# ATSAMD20J16B device description
Architecture: CORTEX-M0PLUS; Family: SAMD; Series: SAMD20
Registers are 8-bit, read-write, reset 0x0 unless marked. A register's access mark holds for its fields unless they carry their own. Offsets are from the block's base; [hi:lo] are bit positions; lines under a group give offsets from that group; {n}, {i} and the like mark numbered series; 'fields as' and 'values as' point back to an identical list; <NAME> marks a mode.

## PORT — Port Module
Instances: PORT 0x41004400, PORT_IOBUS 0x60000000
{0x0+0x80*i} GROUP[{i}] (i=0..1) group
  0x00 DIR 32-bit — Data Direction
    [31:0] DIR — Port Data Direction
  0x04 DIRCLR 32-bit (atomic clear of DIR) — Data Direction Clear
    [31:0] DIRCLR — Port Data Direction Clear
  0x08 DIRSET 32-bit (atomic set of DIR) — Data Direction Set
    [31:0] DIRSET — Port Data Direction Set
  0x0C DIRTGL 32-bit (atomic toggle of DIR) — Data Direction Toggle
    [31:0] DIRTGL — Port Data Direction Toggle
  0x10 OUT 32-bit — Data Output Value
    [31:0] OUT — Port Data Output Value
  0x14 OUTCLR 32-bit (atomic clear of OUT) — Data Output Value Clear
    [31:0] OUTCLR — Port Data Output Value Clear
  0x18 OUTSET 32-bit (atomic set of OUT) — Data Output Value Set
    [31:0] OUTSET — Port Data Output Value Set
  0x1C OUTTGL 32-bit (atomic toggle of OUT) — Data Output Value Toggle
    [31:0] OUTTGL — Port Data Output Value Toggle
  0x20 IN 32-bit ro — Data Input Value
    [31:0] IN — Port Data Input Value
  0x24 CTRL 32-bit — Control
    [31:0] SAMPLING — Input Sampling Mode
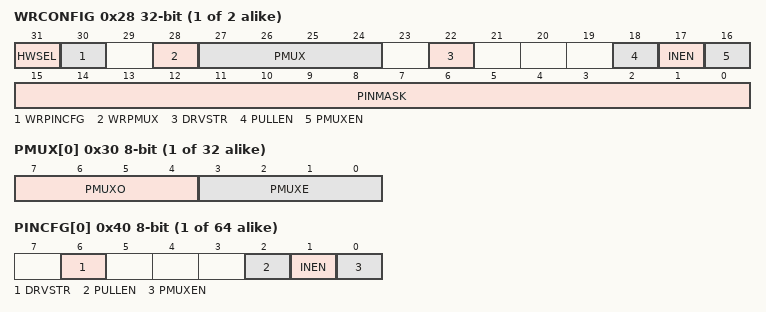
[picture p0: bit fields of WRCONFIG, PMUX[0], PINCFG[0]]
  0x28 WRCONFIG 32-bit wo — Write Configuration
    [31] HWSEL — Half-Word Select
    [30] WRPINCFG — Write PINCFG
    [28] WRPMUX — Write PMUX
    [27:24] PMUX — Peripheral Multiplexing
    [22] DRVSTR — Output Driver Strength Selection
    [18] PULLEN — Pull Enable
    [17] INEN — Input Enable
    [16] PMUXEN — Peripheral Multiplexer Enable
    [15:0] PINMASK — Pin Mask for Multiple Pin Configuration
  {0x30+j} PMUX[{j}] (j=0..15) — Peripheral Multiplexing n
    [7:4] PMUXO — Peripheral Multiplexing Odd
      0=A (Peripheral function A selected); 1=B (Peripheral function B selected); 2=C (Peripheral function C selected); 3=D (Peripheral function D selected); 4=E (Peripheral function E selected); 5=F (Peripheral function F selected); 6=G (Peripheral function G selected); 7=H (Peripheral function H selected)
    [3:0] PMUXE — Peripheral Multiplexing Even
      values as PMUXO
  {0x40+j} PINCFG[{j}] (j=0..31) — Pin Configuration n
    [6] DRVSTR — Output Driver Strength Selection
    [2] PULLEN — Pull Enable
    [1] INEN — Input Enable
    [0] PMUXEN — Peripheral Multiplexer Enable

## TC — Basic Timer Counter
Instances: TC{n} {0x42002000+0x400*n} (n=0..7)
Modes: COUNT8 when TC.CTRLA.MODE=1 (8-bit Counter Mode); COUNT16 when TC.CTRLA.MODE=0 (16-bit Counter Mode); COUNT32 when TC.CTRLA.MODE=2 (32-bit Counter Mode)
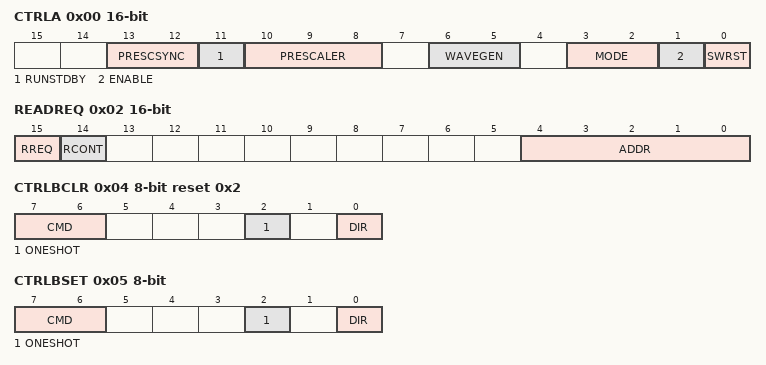
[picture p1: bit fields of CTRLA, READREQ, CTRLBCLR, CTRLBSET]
0x00 CTRLA 16-bit — Control A
  [13:12] PRESCSYNC — Prescaler and Counter Synchronization
    0=GCLK (Reload or reset Counter on next GCLK); 1=PRESC (Reload or reset Counter on next prescaler clock); 2=RESYNC (Reload or reset Counter on next GCLK. Reset prescaler counter)
  [11] RUNSTDBY — Run in Standby
  [10:8] PRESCALER
    0=DIV1 (GCLK_TC); 1=DIV2 (GCLK_TC/2); 2=DIV4 (GCLK_TC/4); 3=DIV8 (GCLK_TC/8); 4=DIV16 (GCLK_TC/16); 5=DIV64 (GCLK_TC/64); 6=DIV256 (GCLK_TC/256); 7=DIV1024 (GCLK_TC/1024)
  [6:5] WAVEGEN — Waveform Generation Operation
    0=NFRQ; 1=MFRQ; 2=NPWM; 3=MPWM
  [3:2] MODE — TC Mode
    0=COUNT16 (Counter in 16-bit mode); 1=COUNT8 (Counter in 8-bit mode); 2=COUNT32 (Counter in 32-bit mode)
  [1] ENABLE
  [0] SWRST — Software Reset
0x02 READREQ 16-bit — Read Request
  [15] RREQ — Read Request
  [14] RCONT — Read Continuously
  [4:0] ADDR — Address
0x04 CTRLBCLR reset 0x2 (atomic clear) — Control B Clear
  [7:6] CMD — Command
    0=NONE (No action); 1=RETRIGGER (Force start, restart or retrigger); 2=STOP (Force stop)
  [2] ONESHOT
  [0] DIR — Counter Direction
0x05 CTRLBSET (atomic set) — Control B Set
  fields as CTRLBCLR
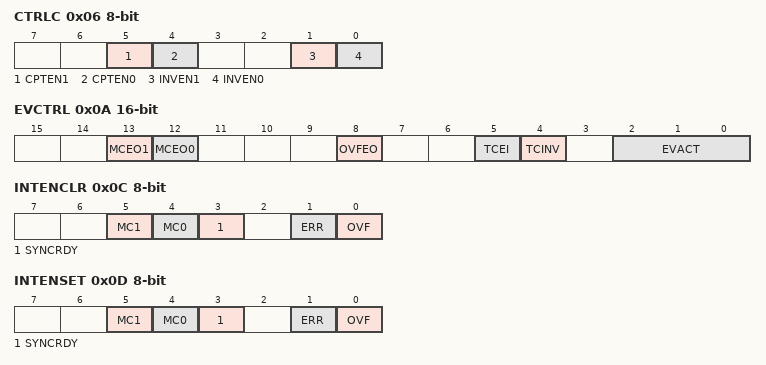
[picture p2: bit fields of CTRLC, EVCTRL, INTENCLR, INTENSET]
0x06 CTRLC — Control C
  [5] CPTEN1 — Capture Channel 1 Enable
  [4] CPTEN0 — Capture Channel 0 Enable
  [1] INVEN1 — Output Waveform 1 Invert Enable
  [0] INVEN0 — Output Waveform 0 Invert Enable
0x08 DBGCTRL — Debug Control
  [0] DBGRUN — Debug Run Mode
0x0A EVCTRL 16-bit — Event Control
  [13] MCEO1 — Match or Capture Channel 1 Event Output Enable
  [12] MCEO0 — Match or Capture Channel 0 Event Output Enable
  [8] OVFEO — Overflow/Underflow Event Output Enable
  [5] TCEI — TC Event Input
  [4] TCINV — TC Inverted Event Input
  [2:0] EVACT — Event Action
    0=OFF (Event action disabled); 1=RETRIGGER (Start, restart or retrigger TC on event); 2=COUNT (Count on event); 3=START (Start TC on event); 5=PPW (Period captured into CC0 Pulse Width in CC1); 6=PWP (Period captured into CC1 Pulse Width on CC0)
0x0C INTENCLR (atomic clear) — Interrupt Enable Clear
  [5] MC1 — Match or Capture Channel 1 Interrupt Enable
  [4] MC0 — Match or Capture Channel 0 Interrupt Enable
  [3] SYNCRDY — Synchronization Ready Interrupt Enable
  [1] ERR — Error Interrupt Enable
  [0] OVF — Overflow Interrupt Enable
0x0D INTENSET (atomic set) — Interrupt Enable Set
  fields as INTENCLR
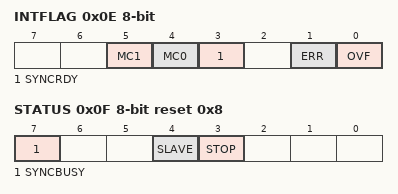
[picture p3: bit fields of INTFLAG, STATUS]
0x0E INTFLAG (atomic clear) — Interrupt Flag Status and Clear
  [5] MC1 — Match or Capture Channel 1
  [4] MC0 — Match or Capture Channel 0
  [3] SYNCRDY — Synchronization Ready
  [1] ERR — Error
  [0] OVF — Overflow
0x0F STATUS ro reset 0x8
  [7] SYNCBUSY — Synchronization Busy
  [4] SLAVE
  [3] STOP
0x10 COUNT <COUNT16> 16-bit — COUNT16 Counter Value
  [15:0] COUNT — Counter Value
{0x18+2i} CC[{i}] (i=0..1) <COUNT16> 16-bit — COUNT16 Compare/Capture
  [15:0] CC — Compare/Capture Value
0x10 COUNT <COUNT32> 32-bit — COUNT32 Counter Value
  [31:0] COUNT — Counter Value
{0x18+4i} CC[{i}] (i=0..1) <COUNT32> 32-bit — COUNT32 Compare/Capture
  [31:0] CC — Compare/Capture Value
0x10 COUNT <COUNT8> — COUNT8 Counter Value
  [7:0] COUNT — Counter Value
0x14 PER <COUNT8> reset 0xFF — COUNT8 Period Value
  [7:0] PER — Period Value
{0x18+i} CC[{i}] (i=0..1) <COUNT8> — COUNT8 Compare/Capture
  [7:0] CC — Compare/Capture Value

## Notices in the file
Copyright (c) 2018 Microchip Technology Inc.
SPDX-License-Identifier: Apache-2.0
Licensed under the Apache License, Version 2.0 (the "License");
you may not use this file except in compliance with the License.
You may obtain a copy of the License at
http://www.apache.org/licenses/LICENSE-2.0
Unless required by applicable law or agreed to in writing, software
distributed under the License is distributed on an "AS IS" BASIS,
WITHOUT WARRANTIES OR CONDITIONS OF ANY KIND, either express or implied.
See the License for the specific language governing permissions and
limitations under the License.
